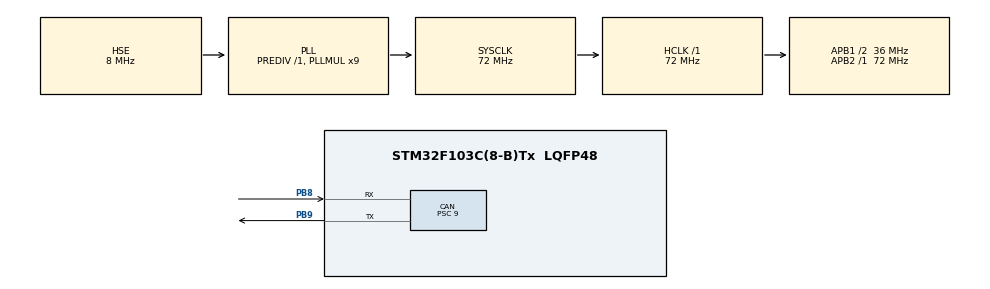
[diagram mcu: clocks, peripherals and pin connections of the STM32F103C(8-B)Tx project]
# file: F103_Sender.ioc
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CAN.ABOM=ENABLE
CAN.BS1=CAN_BS1_11TQ
CAN.BS2=CAN_BS2_4TQ
CAN.CalculateBaudRate=250000
CAN.CalculateTimeBit=4000
CAN.CalculateTimeQuantum=250.0
CAN.NART=ENABLE
CAN.Prescaler=9
CAN.TTCM=DISABLE
FREERTOS.Tasks01=defaultTask,24,128,StartDefaultTask,Default,NULL,Dynamic,NULL,NULL
Mcu.Family=STM32F1
Mcu.Name=STM32F103C(8-B)Tx
Mcu.Package=LQFP48
NVIC.CAN1_RX1_IRQn=true\:5\:0\:false\:false\:true\:true\:true\:true\:true
NVIC.PriorityGroup=NVIC_PRIORITYGROUP_4
NVIC.USB_LP_CAN1_RX0_IRQn=true\:5\:0\:false\:false\:true\:true\:true\:true\:true
PA13.Mode=Serial_Wire
PA13.Signal=SYS_JTMS-SWDIO
PA14.Mode=Serial_Wire
PA14.Signal=SYS_JTCK-SWCLK
PB8.Mode=CAN_Activate
PB8.Signal=CAN_RX
PB9.Mode=CAN_Activate
PB9.Signal=CAN_TX
PC14-OSC32_IN.Mode=LSE-External-Oscillator
PC14-OSC32_IN.Signal=RCC_OSC32_IN
PC15-OSC32_OUT.Mode=LSE-External-Oscillator
PC15-OSC32_OUT.Signal=RCC_OSC32_OUT
PD0-OSC_IN.Mode=HSE-External-Oscillator
PD0-OSC_IN.Signal=RCC_OSC_IN
PD1-OSC_OUT.Mode=HSE-External-Oscillator
PD1-OSC_OUT.Signal=RCC_OSC_OUT
ProjectManager.HeapSize=0x200
ProjectManager.StackSize=0x400
ProjectManager.TargetToolchain=MDK-ARM V5.32
RCC.AHBFreq_Value=72000000
RCC.APB1CLKDivider=RCC_HCLK_DIV2
RCC.APB1Freq_Value=36000000
RCC.APB1TimFreq_Value=72000000
RCC.APB2Freq_Value=72000000
RCC.APB2TimFreq_Value=72000000
RCC.HCLKFreq_Value=72000000
RCC.PLLMUL=RCC_PLL_MUL9
RCC.PLLSourceVirtual=RCC_PLLSOURCE_HSE
RCC.SYSCLKFreq_VALUE=72000000
RCC.SYSCLKSource=RCC_SYSCLKSOURCE_PLLCLK
RCC.USBFreq_Value=72000000
VP_FREERTOS_VS_CMSIS_V2.Mode=CMSIS_V2
board=custom

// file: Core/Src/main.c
/* USER CODE BEGIN Header */
/**
  ******************************************************************************
  * @file           : main.c
  * @brief          : Main program body
  ******************************************************************************
  * @attention
  *
  * Copyright (c) 2026 STMicroelectronics.
  * All rights reserved.
  *
  * This software is licensed under terms that can be found in the LICENSE file
  * in the root directory of this software component.
  * If no LICENSE file comes with this software, it is provided AS-IS.
  *
  ******************************************************************************
  */
/* USER CODE END Header */
#include "main.h"
#include "cmsis_os.h"
#include "can.h"
#include "gpio.h"

/* USER CODE BEGIN Includes */
#include <string.h>
#include "Int_can.h"
#include "App_can.h"
/* USER CODE END Includes */

void SystemClock_Config(void);
void MX_FREERTOS_Init(void);

int main(void)
{

  /* MCU Configuration--------------------------------------------------------*/

  /* Reset of all peripherals, Initializes the Flash interface and the Systick. */
  HAL_Init();

  /* Configure the system clock */
  SystemClock_Config();

  /* Initialize all configured peripherals */
  MX_GPIO_Init();
  MX_CAN_Init();
  /* USER CODE BEGIN 2 */
  if (INT_CAN_Start() != HAL_OK)
  {
      Error_Handler();
  }

  APP_CAN_Init();
  /* USER CODE END 2 */

  /* Init scheduler */
  osKernelInitialize();

  /* Call init function for freertos objects (in cmsis_os2.c) */
  MX_FREERTOS_Init();

  /* Start scheduler */
  osKernelStart();

  /* We should never get here as control is now taken by the scheduler */

  /* Infinite loop */
  while (1)
  {

    /* USER CODE BEGIN 3 */
  /* motor test moved to CAN_Motor_Test_Task (freertos.c) */
  }
  /* USER CODE END 3 */
}

void SystemClock_Config(void)
{
  RCC_OscInitTypeDef RCC_OscInitStruct = {0};
  RCC_ClkInitTypeDef RCC_ClkInitStruct = {0};

  /** Initializes the RCC Oscillators according to the specified parameters
  * in the RCC_OscInitTypeDef structure.
  */
  RCC_OscInitStruct.OscillatorType = RCC_OSCILLATORTYPE_HSE;
  RCC_OscInitStruct.HSEState = RCC_HSE_ON;
  RCC_OscInitStruct.HSEPredivValue = RCC_HSE_PREDIV_DIV1;
  RCC_OscInitStruct.HSIState = RCC_HSI_ON;
  RCC_OscInitStruct.PLL.PLLState = RCC_PLL_ON;
  RCC_OscInitStruct.PLL.PLLSource = RCC_PLLSOURCE_HSE;
  RCC_OscInitStruct.PLL.PLLMUL = RCC_PLL_MUL9;
  if (HAL_RCC_OscConfig(&RCC_OscInitStruct) != HAL_OK)
  {
    Error_Handler();
  }

  /** Initializes the CPU, AHB and APB buses clocks
  */
  RCC_ClkInitStruct.ClockType = RCC_CLOCKTYPE_HCLK|RCC_CLOCKTYPE_SYSCLK
                              |RCC_CLOCKTYPE_PCLK1|RCC_CLOCKTYPE_PCLK2;
  RCC_ClkInitStruct.SYSCLKSource = RCC_SYSCLKSOURCE_PLLCLK;
  RCC_ClkInitStruct.AHBCLKDivider = RCC_SYSCLK_DIV1;
  RCC_ClkInitStruct.APB1CLKDivider = RCC_HCLK_DIV2;
  RCC_ClkInitStruct.APB2CLKDivider = RCC_HCLK_DIV1;

  if (HAL_RCC_ClockConfig(&RCC_ClkInitStruct, FLASH_LATENCY_2) != HAL_OK)
  {
    Error_Handler();
  }
}

void Error_Handler(void)
{
  __disable_irq();
  while (1)
  {
  }
}

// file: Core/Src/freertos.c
/* USER CODE BEGIN Header */
/**
  ******************************************************************************
  * File Name          : freertos.c
  * Description        : Code for freertos applications
  ******************************************************************************
  * @attention
  *
  * Copyright (c) 2026 STMicroelectronics.
  * All rights reserved.
  *
  * This software is licensed under terms that can be found in the LICENSE file
  * in the root directory of this software component.
  * If no LICENSE file comes with this software, it is provided AS-IS.
  *
  ******************************************************************************
  */
/* USER CODE END Header */

#include "FreeRTOS.h"
#include "task.h"
#include "main.h"
#include "cmsis_os.h"

/* USER CODE BEGIN Includes */
#include "App_MotorCan.h"

/* USER CODE END Includes */

/* USER CODE BEGIN Variables */

/* Definitions for CAN_Motor_TestTask */
osThreadId_t CAN_Motor_TestTaskHandle;
const osThreadAttr_t CAN_Motor_TestTask_attributes = {
  .name = "CAN_Motor_TestTask",
  .stack_size = 128 * 4,
  .priority = (osPriority_t) osPriorityNormal,
};

/* USER CODE END Variables */
/* Definitions for defaultTask */
osThreadId_t defaultTaskHandle;
const osThreadAttr_t defaultTask_attributes = {
  .name = "defaultTask",
  .stack_size = 128 * 4,
  .priority = (osPriority_t) osPriorityNormal,
};

/* USER CODE BEGIN FunctionPrototypes */

void CAN_Motor_Test_Task(void *argument);

/* USER CODE END FunctionPrototypes */

void StartDefaultTask(void *argument);

void MX_FREERTOS_Init(void); /* (MISRA C 2004 rule 8.1) */

void MX_FREERTOS_Init(void) {

  /* Create the thread(s) */
  /* creation of defaultTask */
  defaultTaskHandle = osThreadNew(StartDefaultTask, NULL, &defaultTask_attributes);

  /* USER CODE BEGIN RTOS_THREADS */
  /* creation of CAN_Motor_TestTask */
  CAN_Motor_TestTaskHandle = osThreadNew(CAN_Motor_Test_Task, NULL, &CAN_Motor_TestTask_attributes);
  /* USER CODE END RTOS_THREADS */

}

void StartDefaultTask(void *argument)
{
  for(;;)
  {
    osDelay(1);
  }
}

/* USER CODE BEGIN Application */
/**
  * @brief  Function implementing the CAN motor test thread.
  * @param  argument: Not used
  * @retval None
  */
void CAN_Motor_Test_Task(void *argument)
{
  /* 测试序列：低速/中速/较高速/停止/反转，每档保持 5 秒后循环
   * 顺序   CAN速度命令   目标转速
   * 1     +50         +8.45 RPM
   * 2     +100        +16.9 RPM
   * 3     +200        +33.8 RPM
   * 4     0 (STOP)    0 RPM
   * 5     -100        -16.9 RPM
   */
  // const int16_t cmd_seq[] = {50, 100, 200, 0, -100};
  // const uint32_t hold_ms = 5000;      /* 每档保持时长 */
  // const uint32_t period_ms = 50;      /* 周期心跳间隔 */
  // const uint32_t send_count = hold_ms / period_ms;

  // for (;;)
  // {
  //   for (int i = 0; i < (int)(sizeof(cmd_seq) / sizeof(cmd_seq[0])); i++)
  //   {
  //     for (uint32_t j = 0; j < send_count; j++)
  //     {
  //       if (cmd_seq[i] == 0)
  //         App_MotorCan_SendStop();
  //       else
  //         App_MotorCan_SendSpeed(cmd_seq[i]);
  //       osDelay(period_ms);
  //     }
  //   }
  // }

  /* 循环测试序列：
   * 1) +100 稳定运行，记录实际转速
   * 2) +200 稳定后记录 ActRPM / Err / I / PWM
   * 3) 切回 +100，观察能否重新稳定在 16.9 RPM
   * 4) 发送 STOP，确认电机停止
   */
  const int16_t cmd_seq[] = {100, 200, 100, 0};
  const uint32_t hold_ms = 40000;      /* 每档保持时长 */
  const uint32_t period_ms = 50;      /* 周期心跳间隔 */
  const uint32_t send_count = hold_ms / period_ms;

  for (;;)
  {
    for (uint32_t i = 0; i < sizeof(cmd_seq) / sizeof(cmd_seq[0]); i++)
    {
      uint32_t j;
      for (j = 0; j < send_count; j++)
      {
        if (cmd_seq[i] == 0)
          App_MotorCan_SendStop();
        else
          App_MotorCan_SendSpeed(cmd_seq[i]);
        osDelay(period_ms);
      }
    }
  }
}

/* USER CODE END Application */
